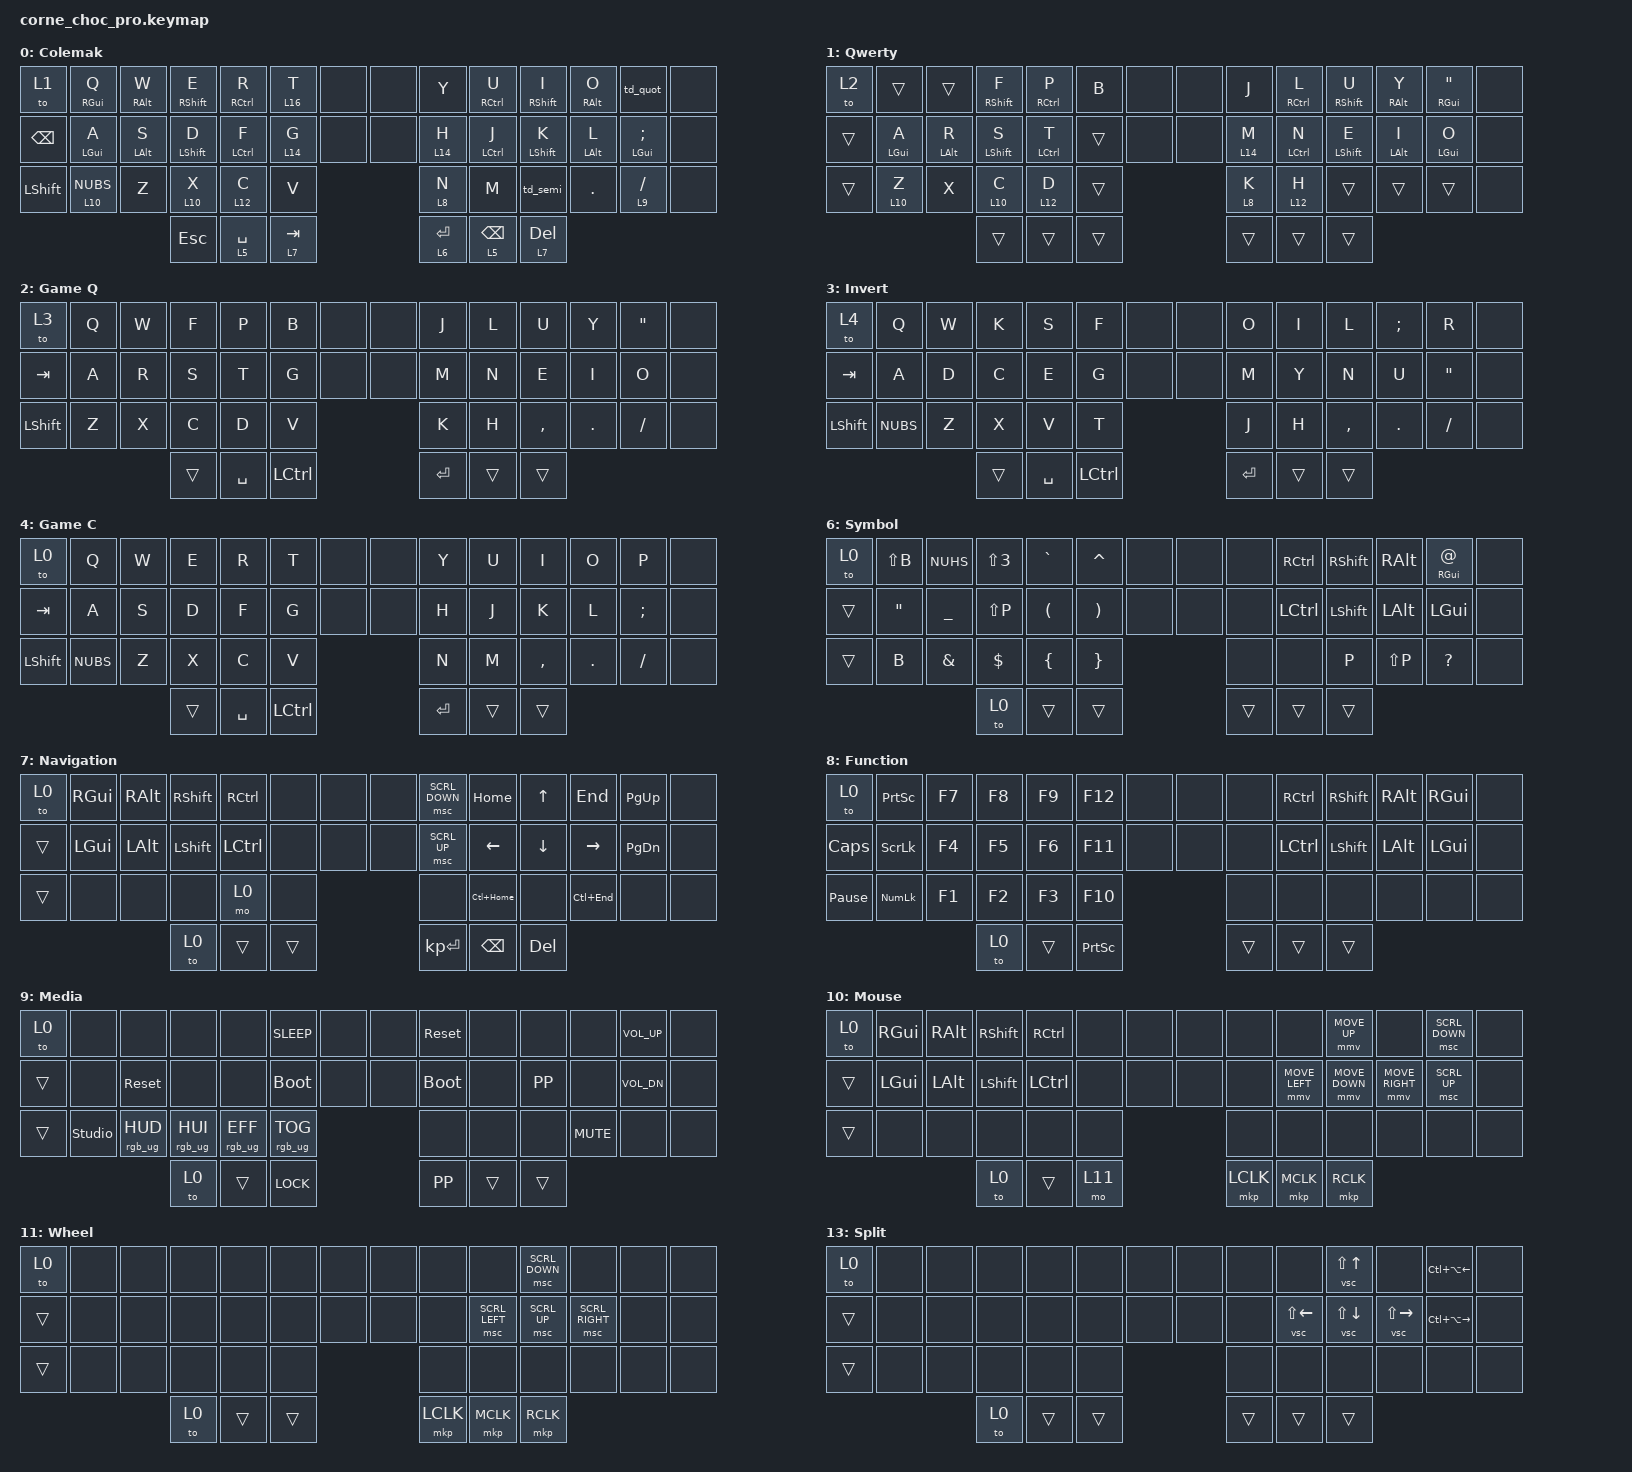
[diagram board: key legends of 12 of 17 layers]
/*
 * Copyright (c) 2020 The ZMK Contributors
 *
 * SPDX-License-Identifier: MIT
 */

#include <behaviors.dtsi>
#include <dt-bindings/zmk/bt.h>
#include <dt-bindings/zmk/keys.h>
#include <dt-bindings/zmk/pointing.h>
#include <dt-bindings/zmk/rgb.h>

// ┏━━━━━━━━━━━━━━━━━━━━━━━━━━━━━━━━━━━━━━━━━━━━━━━━━━━━━━━━━━━━━━━━━━━━━━━━━━━━━━━━━━━━━━━━━━━━━━━━━┓
// ┃                                 CORNE CHOC PRO KEYMAP CONFIGURATION                             ┃
// ┗━━━━━━━━━━━━━━━━━━━━━━━━━━━━━━━━━━━━━━━━━━━━━━━━━━━━━━━━━━━━━━━━━━━━━━━━━━━━━━━━━━━━━━━━━━━━━━━━━┛

#define BASE 0
#define QWER 1
#define QGAM 2
#define INVR 3
#define GAME 4
#define NUMB 5
#define SYMB 6
#define NAVI 7
#define FUNC 8
#define MEDI 9
#define MOUS 10
#define MWHL 11
#define CODE 12
#define CSLP 13
#define TILE 14
#define TSIZ 15
#define BLUE 16
#define TERM 17

/ {
    chosen { zmk,physical-layout = &default_layout; };

    behaviors {
        hml: home_row_mod_left {
            compatible = "zmk,behavior-hold-tap";
            #binding-cells = <2>;
            flavor = "balanced";
            require-prior-idle-ms = <200>;
            tapping-term-ms = <280>;
            quick-tap-ms = <175>;
            bindings = <&kp>, <&kp>;

            hold-trigger-key-positions = <7 8 9 10 11 12 13 21 22 23 24 25 26 34 35 36 37 38 39 40 41 42 43 44 27 45 20 6>; // List of keys on the right and thumbs
            hold-trigger-on-release;
        };

        hmr: home_row_mod_right {
            compatible = "zmk,behavior-hold-tap";
            #binding-cells = <2>;
            flavor = "balanced";
            require-prior-idle-ms = <200>;
            tapping-term-ms = <280>;
            quick-tap-ms = <175>;
            bindings = <&kp>, <&kp>;

            hold-trigger-key-positions = <0 1 2 3 4 5 6 14 15 16 17 18 19 28 29 30 31 32 40 41 42 43 44 19 20 33 21 7 45>; // List of keys on the left and thumbs
            hold-trigger-on-release;
        };

        td_quot: td_quot {
            compatible = "zmk,behavior-tap-dance";
            label = "TD_QUOT";
            #binding-cells = <0>;
            bindings = <&mt RGUI P>, <&kp AT>;
        };

        td_semi: td_semi {
            compatible = "zmk,behavior-tap-dance";
            label = "TD_SEMI";
            #binding-cells = <0>;
            bindings = <&kp COMMA>, <&kp P>;
        };
    };

    macros {
        vsc: visual_studio_code {
            compatible = "zmk,behavior-macro-one-param";
            #binding-cells = <1>;
            bindings = <&kp LC(N) &macro_param_1to1 &kp MACRO_PLACEHOLDER>;
        };
    };
};

/ {
    combos {
        compatible = "zmk,combos";

        AA {
            bindings = <&kp RA(W)>;
            key-positions = <11 12>;
        };

        AE {
            bindings = <&kp RA(R)>;
            key-positions = <11 10>;
        };

        OE {
            bindings = <&kp RA(NUBS)>;
            key-positions = <26 25>;
        };
    };

    keymap {
        compatible = "zmk,keymap";

        default_layer {
            // ┏━━━━━━━━━━━━━━━━━━━━━━━━━━━━━━━━━━━━━━━━━━━━━━━━━┓
            // ┃                                                 ┃

            label = "BASE";           //               ┃
            display-name = "Colemak"; //               ┃
            // ┃      note: If OS layout is COLEMAK              ┃
            // ┃                                                 ┃
            // ┗━━━━━━━━━━━━━━━━━━━━━━━━━━━━━━━━━━━━━━━━━━━━━━━━━┛
            // --------------------------------------------------------------------------------
            // | QWER |  Q  |  W  |  F  |  P  |  B  |     |     |  J  |  L   |  U  |  Y  |  '  |  |
            // | BSPC |  A  |  R  |  S  |  T  |  G  |     |     |  M  |  N   |  E  |  I  |  O  |  |
            // | SHFT |  Z  |  X  |  C  |  D  |  V  |           |  K  |  H   |  ,  |  .  |  /  |  |
            //                    | ESC | SPC | TAB |           | ENT | BSPC | DEL |
            // --------------------------------------------------------------------------------
            // |    | RGUI | RALT | RSHFT | RCTRL | BLUE |     |     |      | RCTRL | RSHFT | RALT | RGUI |  |
            // |    | GUI  | ALT  | SHFT  | CTRL  | TILE |     |     | TILE | CTRL  | SHFT  | ALT  | GUI  |  |
            // |    |      |      | MOUSE | CODE  | FUNC |           | FUNC | CODE  |       | COMP | MEDI |  |
            //                    |       | NUMB  | NAVI |           | SYMB | NUMB  | NAVI  |

            bindings = <
&to 1      &hml RGUI Q  &hml RALT W  &hml RSHFT E  &hml RCTRL R  &lt 16 T   &none  &none  &kp Y      &hmr RCTRL U  &hmr RSHFT I  &hmr RALT O  &td_quot        &none
&kp BSPC   &hml LGUI A  &hml LALT S  &hml LSHFT D  &hml LCTRL F  &lt 14 G   &none  &none  &lt 14 H   &hmr LCTRL J  &hmr LSHFT K  &hmr LALT L  &hmr LGUI SEMI  &none
&kp LSHFT  &lt 10 NUBS  &kp Z        &lt 10 X      &lt 12 C      &kp V                    &lt 8 N    &kp M         &td_semi      &kp DOT      &lt 9 FSLH      &none
                                     &kp ESC       &lt 5 SPACE   &lt 7 TAB                &lt 6 RET  &lt 5 BSPC    &lt 7 DEL
            >;

            sensor-bindings = <&inc_dec_kp C_VOL_DN C_VOL_UP &inc_dec_kp PG_UP PG_DN &inc_dec_kp C_PREV C_NEXT &inc_dec_kp C_BRI_DN C_BRI_UP>;
        };

        qwerty_layer {
            // ┏━━━━━━━━━━━━━━━━━━━━━━━━━━━━━━━━━━━━━━━━━━━━━━━━━┓
            // ┃                                                 ┃

            label = "QWER";          //                ┃
            display-name = "Qwerty"; //                ┃
            // ┃      note: If OS layout is QWERTY               ┃
            // ┃                                                 ┃
            // ┗━━━━━━━━━━━━━━━━━━━━━━━━━━━━━━━━━━━━━━━━━━━━━━━━━┛
            // -----------------------------------------------------------------------------------------
            // | QGAM |  Q  |  W  |  E  |  R  |  T   |       |       |  Y  |  U   |  I  |  O  |  P  |   |
            // | BSPC |  A  |  S  |  D  |  F  |  G   |       |       |  H  |  J   |  K  |  L  |  '  |   |
            // | SHFT |  Z  |  X  |  C  |  V  |  B   |               |  N  |  M   |  ,  |  .  |  /  |   |
            //                    | ESC | SPC | TAB  |               | ENT | BSPC | DEL |
            // -----------------------------------------------------------------------------------------
            // |    | RGUI | RALT | RSHFT | RCTRL | BLUE |     |     |      | RCTRL | RSHFT | RALT | RGUI |  |
            // |    | GUI  | ALT  | SHFT  | CTRL  | TILE |     |     | TILE | CTRL  | SHFT  | ALT  | GUI  |  |
            // |    |      | COMP |       | CODE  | FUNC |           | FUNC | CODE  |       | COMP | MEDI |  |
            //                    |       | NUMB  | NAVI |           | SYMB | NUMB  | NAVI  |

            bindings = <
&to 2   &trans       &trans       &hml RSHFT F  &hml RCTRL P  &kp B   &none  &none  &kp J     &hmr RCTRL L  &hmr RSHFT U  &hmr RALT Y  &hmr RGUI DQT  &none
&trans  &hml LGUI A  &hml LALT R  &hml LSHFT S  &hml LCTRL T  &trans  &none  &none  &lt 14 M  &hmr LCTRL N  &hmr LSHFT E  &hmr LALT I  &hmr LGUI O    &none
&trans  &lt 10 Z     &kp X        &lt 10 C      &lt 12 D      &trans                &lt 8 K   &lt 12 H      &trans        &trans       &trans         &none
                                  &trans        &trans        &trans                &trans    &trans        &trans
            >;

            sensor-bindings = <&inc_dec_kp C_VOL_DN C_VOL_UP &inc_dec_kp PG_UP PG_DN &inc_dec_kp C_PREV C_NEXT &inc_dec_kp C_BRI_DN C_BRI_UP>;
        };

        qwerty_game_layer {
            // ┏━━━━━━━━━━━━━━━━━━━━━━━━━━━━━━━━━━━━━━━━━━━━━━━━━┓
            // ┃                                                 ┃

            label = "QGAM";          //                ┃
            display-name = "Game Q"; //                ┃
            // ┃                                                 ┃
            // ┗━━━━━━━━━━━━━━━━━━━━━━━━━━━━━━━━━━━━━━━━━━━━━━━━━┛
            // -----------------------------------------------------------------------------------------
            // | INVR |  Q  |  W  |  E  |  R  |  T   |       |       |  Y  |  U   |  I  |  O  |  P  |   |
            // | CTRL |  A  |  S  |  D  |  F  |  G   |       |       |  H  |  J   |  K  |  L  |  '  |   |
            // | SHFT |  Z  |  X  |  C  |  V  |  B   |               |  N  |  M   |  ,  |  .  |  /  |   |
            //                    | ESC | SPC | TAB  |               | ENT | BSPC | DEL |
            // -----------------------------------------------------------------------------------------
            // |      |     |     |     |     |     |       |       |     |      |     |     |     |      |
            // |      |     |     |     |     |     |       |       |     |      |     |     |     |      |
            // |      |     |     |     |     |     |               |     |      |     |     |     |      |
            //                    |     |     |     |               |     |      |     |

            bindings = <
&to 3      &kp Q  &kp W  &kp F   &kp P      &kp B      &none  &none  &kp J    &kp L   &kp U      &kp Y    &kp DQT   &none
&kp TAB    &kp A  &kp R  &kp S   &kp T      &kp G      &none  &none  &kp M    &kp N   &kp E      &kp I    &kp O     &none
&kp LSHFT  &kp Z  &kp X  &kp C   &kp D      &kp V                    &kp K    &kp H   &kp COMMA  &kp DOT  &kp FSLH  &none
                         &trans  &kp SPACE  &kp LCTRL                &kp RET  &trans  &trans
            >;

            sensor-bindings = <&inc_dec_kp C_VOL_DN C_VOL_UP &inc_dec_kp PG_UP PG_DN &inc_dec_kp C_PREV C_NEXT &inc_dec_kp C_BRI_DN C_BRI_UP>;
        };

        invert_game_layer {
            // ┏━━━━━━━━━━━━━━━━━━━━━━━━━━━━━━━━━━━━━━━━━━━━━━━━━┓
            // ┃                                                 ┃

            label = "INVR";          //                ┃
            display-name = "Invert"; //                ┃
            // ┃                                                 ┃
            // ┗━━━━━━━━━━━━━━━━━━━━━━━━━━━━━━━━━━━━━━━━━━━━━━━━━┛
            // -----------------------------------------------------------------------------------------
            // | GAME |  Q  |  W  |  E  |  R  |  T   |       |       |  Y  |  U   |  I  |  O  |  P  |   |
            // | CTRL |  A  |  S  |  D  |  F  |  G   |       |       |  H  |  J   |  K  |  L  |  '  |   |
            // | SHFT |  Z  |  X  |  C  |  V  |  B   |               |  N  |  M   |  ,  |  .  |  /  |   |
            //                    | ESC | SPC | TAB  |               | ENT | BSPC | DEL |
            // -----------------------------------------------------------------------------------------
            // |      |     |     |     |     |     |       |       |     |      |     |     |     |      |
            // |      |     |     |     |     |     |       |       |     |      |     |     |     |      |
            // |      |     |     |     |     |     |               |     |      |     |     |     |      |
            //                    |     |     |     |               |     |      |     |

            bindings = <
&to 4      &kp Q     &kp W  &kp K   &kp S      &kp F      &none  &none  &kp O    &kp I   &kp L      &kp SEMI  &kp R     &none
&kp TAB    &kp A     &kp D  &kp C   &kp E      &kp G      &none  &none  &kp M    &kp Y   &kp N      &kp U     &kp DQT   &none
&kp LSHFT  &kp NUBS  &kp Z  &kp X   &kp V      &kp T                    &kp J    &kp H   &kp COMMA  &kp DOT   &kp FSLH  &none
                            &trans  &kp SPACE  &kp LCTRL                &kp RET  &trans  &trans
            >;

            sensor-bindings = <&inc_dec_kp C_VOL_DN C_VOL_UP &inc_dec_kp PG_UP PG_DN &inc_dec_kp C_PREV C_NEXT &inc_dec_kp C_BRI_DN C_BRI_UP>;
        };

        colemak_game_layer {
            // ┏━━━━━━━━━━━━━━━━━━━━━━━━━━━━━━━━━━━━━━━━━━━━━━━━━┓
            // ┃                                                 ┃

            label = "GAME";
            display-name = "Game C";

            // ┃                                                 ┃
            // ┗━━━━━━━━━━━━━━━━━━━━━━━━━━━━━━━━━━━━━━━━━━━━━━━━━┛
            // -----------------------------------------------------------------------------------------
            // | BASE |  Q  |  W  |  F  |  P  |  B   |     |     |  J  |  L   |  U  |  Y  |  '  |  |
            // | CTRL |  A  |  R  |  S  |  T  |  G   |     |     |  M  |  N   |  E  |  I  |  O  |  |
            // | SHFT |  Z  |  X  |  C  |  D  |  V   |           |  K  |  H   |  ,  |  .  |  /  |  |
            //                    | ESC | SPC | TAB  |           | ENT | BSPC | DEL |
            // -----------------------------------------------------------------------------------------
            // |      |     |     |     |     |     |       |       |     |      |     |     |     |   |
            // |      |     |     |     |     |     |       |       |     |      |     |     |     |   |
            // |      |     |     |     |     |     |               |     |      |     |     |     |   |
            //                    |     |     |     |               |     |      |     |

            bindings = <
&to 0      &kp Q     &kp W  &kp E   &kp R      &kp T      &none  &none  &kp Y    &kp U   &kp I      &kp O    &kp P     &none
&kp TAB    &kp A     &kp S  &kp D   &kp F      &kp G      &none  &none  &kp H    &kp J   &kp K      &kp L    &kp SEMI  &none
&kp LSHFT  &kp NUBS  &kp Z  &kp X   &kp C      &kp V                    &kp N    &kp M   &kp COMMA  &kp DOT  &kp FSLH  &none
                            &trans  &kp SPACE  &kp LCTRL                &kp RET  &trans  &trans
            >;

            sensor-bindings = <&inc_dec_kp C_VOL_DN C_VOL_UP &inc_dec_kp PG_UP PG_DN &inc_dec_kp C_PREV C_NEXT &inc_dec_kp C_BRI_DN C_BRI_UP>;
        };

        number_layer {
            // ┏━━━━━━━━━━━━━━━━━━━━━━━━━━━━━━━━━━━━━━━━━━━━━━━━━┓
            // ┃                                                 ┃

            label = "NUMB";
            display-name = "Number";

            // ┃                                                 ┃
            // ┗━━━━━━━━━━━━━━━━━━━━━━━━━━━━━━━━━━━━━━━━━━━━━━━━━┛
            // -----------------------------------------------------------------------------------------
            // | BASE |  !  |     |      |     |     |       |       |     |  7  |  8  |  9  |  0  |   |
            // |      |  +  |  =  | "-"  |  <  |  >  |       |       |  ,  |  4  |  5  |  6  |     |   |
            // |      |  ~  |  %  |  *   |  [  |  ]  |               |  .  |  1  |  2  |  3  |  /  |   |
            //                    | BASE | SPC | TAB |               | ENT |  0  | DEL |
            // -----------------------------------------------------------------------------------------
            // |      | RGUI | RALT | RSHF | RCTL |     |       |       |     | RCTL | RSHF | RALT | RGUI |   |
            // |      | GUI  | ALT  | SHFT | CTRL |     |       |       |     | CTRL | SHFT | ALT  | GUI  |   |
            // |      |      |      |      |      |     |               |     |      |      |      |      |   |
            //                      |      |      |     |               |     |      |      |

            bindings = <
&to 0   &mt RGUI EXCL  &kp RALT        &kp RSHFT        &kp RCTRL     &none     &none  &none  &kp LS(SEMICOLON)  &mt RCTRL N7  &mt RSHFT N8  &mt RALT N9  &mt (RGUI) LS(LC(UP_ARROW))    &none
&trans  &mt LGUI PLUS  &mt LALT EQUAL  &mt LSHFT MINUS  &mt LCTRL LT  &kp GT    &none  &none  &kp COMMA          &mt LCTRL N4  &mt LSHFT N5  &mt LALT N6  &mt (LGUI) LS(LC(DOWN_ARROW))  &none
&trans  &kp PIPE       &kp PRCNT       &kp STAR         &kp LBKT      &kp RBKT                &kp DOT            &kp N1        &kp N2        &kp N3       &kp FSLH                       &none
                                       &to 0            &kp SPACE     &kp TAB                 &kp RET            &kp N0        &trans
            >;
        };

        symbol_layer {
            // ┏━━━━━━━━━━━━━━━━━━━━━━━━━━━━━━━━━━━━━━━━━━━━━━━━━┓
            // ┃                                                 ┃

            label = "SYMB";
            display-name = "Symbol";

            // ┃                                                 ┃
            // ┗━━━━━━━━━━━━━━━━━━━━━━━━━━━━━━━━━━━━━━━━━━━━━━━━━┛
            // -----------------------------------------------------------------------------------------
            // | BASE | "|" |  #  |  £  |  `  |  "  |       |       |  ^  |      |      |     |  "  |   |
            // |      |  @  |  _  |  :  |  (  |  )  |       |       |     |      |      |     |     |   |
            // |      |  \  |  &  |  $  |  {  |  }  |               |     |      |  ;   |  :  |  ?  |   |
            //                    |     |     |     |               |     |      |      |
            // -----------------------------------------------------------------------------------------
            // |      |     |     |     |     |     |       |       |     |      |      |     |     |   |
            // |      |     |     |     |     |     |       |       |     | CTRL | SHFT | ALT | GUI |   |
            // |      |     |     |     |     |     |               |     |      |      |     |     |   |
            //                    |     |     |     |               |     |      |      |

            bindings = <
&to 0   &kp LS(B)  &kp NUHS   &kp LS(N3)  &kp GRAVE  &kp CARET  &none  &none  &none   &kp RCTRL  &kp RSHFT  &kp RALT   &mt RGUI AT  &none
&trans  &kp DQT    &kp UNDER  &kp LS(P)   &kp LPAR   &kp RPAR   &none  &none  &none   &kp LCTRL  &kp LSHFT  &kp LALT   &kp LGUI     &none
&trans  &kp B      &kp AMPS   &kp DLLR    &kp LBRC   &kp RBRC                 &none   &none      &kp P      &kp LS(P)  &kp QMARK    &none
                              &to 0       &trans     &trans                   &trans  &trans     &trans
            >;
        };

        navigation_layer {
            // ┏━━━━━━━━━━━━━━━━━━━━━━━━━━━━━━━━━━━━━━━━━━━━━━━━━┓
            // ┃                                                 ┃

            label = "NAV";
            display-name = "Navigation";

            // ┃                                                 ┃
            // ┗━━━━━━━━━━━━━━━━━━━━━━━━━━━━━━━━━━━━━━━━━━━━━━━━━┛
            // -----------------------------------------------------------------------------------------
            // | BASE |      |      |      |      |      |     |     | TOP | HOME |  UP  | END   | PGUP |   |
            // |      | SEL  | LOAD | SAVE | NWTB |      |     |     | <<  | LEFT | DOWN | RIGHT | PGDN |   |
            // |      | UNDO | CUT  | COPY | PAST | REDO |           |     | TOP  |      | BTTM  |      |   |
            //                      |      |      |      |           |     |      |      |
            // -----------------------------------------------------------------------------------------
            // |      | RGUI | RALT | RSHF | RCTL |     |     |     |     |      |     |     |     |   |
            // |      | GUI  | ALT  | SHFT | CTRL |     |     |     |     |      |     |     |     |   |
            // |      |      |      |      |      |     |           |     |      |     |     |     |   |
            //                      |      |      |     |           |     |      |     |

            bindings = <
&to 0   &kp RGUI  &kp RALT  &kp RSHIFT  &kp RCTRL  &none   &none  &none  &msc SCRL_DOWN  &kp HOME       &kp UP      &kp END      &kp PG_UP  &none
&trans  &kp LGUI  &kp LALT  &kp LSHFT   &kp LCTRL  &none   &none  &none  &msc SCRL_UP    &kp LEFT       &kp DOWN    &kp RIGHT    &kp PG_DN  &none
&trans  &none     &none     &none       &mo 0      &none                 &none           &kp LC(HOME)   &none       &kp LC(END)  &none      &none
                            &to 0       &trans     &trans                &kp KP_ENTER    &kp BACKSPACE  &kp DELETE
            >;
        };

        function_layer {
            // ┏━━━━━━━━━━━━━━━━━━━━━━━━━━━━━━━━━━━━━━━━━━━━━━━━━┓
            // ┃                                                 ┃

            label = "FUNC";
            display-name = "Function";

            // ┃                                                 ┃
            // ┗━━━━━━━━━━━━━━━━━━━━━━━━━━━━━━━━━━━━━━━━━━━━━━━━━┛
            // -----------------------------------------------------------------------------------------
            // | BASE | PRNT | f12 | f7 | f8  | f9 | f12 |     |     |     |     |     |     |     |   |
            // | CAPS | SCLK | f11 | f4 | f5  | f6 | f11 |     |     |     |     |     |     |     |   |
            // | PAUS | NMLK | f10 | f1 | f2  | f3 | f10 |           |     |     |     |     |     |   |
            //                          |     |    |     |           |     |     |     |
            // -----------------------------------------------------------------------------------------
            // |      |     |     |     |     |     |     |     |     | RCTL | RSHF | RALT | RGUI |   |
            // |      |     |     |     |     |     |     |     |     | CTRL | SHFT | ALT  | GUI  |   |
            // |      |     |     |     |     |     |           |     |      |      |      |      |   |
            //                    |     |     |     |           |     |      |      |

            bindings = <
&to 0            &kp PSCRN   &kp F7  &kp F8  &kp F9  &kp F12    &none  &none  &none   &kp RCTRL  &kp RSHFT  &kp RALT  &kp RGUI  &none
&kp CAPS         &kp SLCK    &kp F4  &kp F5  &kp F6  &kp F11    &none  &none  &none   &kp LCTRL  &kp LSHFT  &kp LALT  &kp LGUI  &none
&kp PAUSE_BREAK  &kp KP_NUM  &kp F1  &kp F2  &kp F3  &kp F10                  &none   &none      &none      &none     &none     &none
                                     &to 0   &trans  &kp PSCRN                &trans  &trans     &trans
            >;
        };

        media_layer {
            // ┏━━━━━━━━━━━━━━━━━━━━━━━━━━━━━━━━━━━━━━━━━━━━━━━━━┓
            // ┃                                                 ┃

            label = "MEDI";
            display-name = "Media";

            // ┃                                                 ┃
            // ┗━━━━━━━━━━━━━━━━━━━━━━━━━━━━━━━━━━━━━━━━━━━━━━━━━┛
            // -----------------------------------------------------------------------------------------
            // | BASE |        |      |      |       |  PWR   |     |     |      |      |      |      | VOL+ |   |
            // |      |        | RSET |      |       |  BOOT  |     |     | BOOT |      | PLAY |      | VOL- |   |
            // |      | STUDIO | Hue- | Hue+ | Effct | RgbTog |           |      |      |      | MUTE |      |   |
            //                        |      |       |  LOCK  |           | PLAY |      |      |
            // -----------------------------------------------------------------------------------------
            // |      |     |     |     |     |     |      |      |     |      |     |     |     |   |
            // |      |     |     |     |     |     |      |      |     |      |     |     |     |   |
            // |      |     |     |     |     |     |             |     |      |     |     |     |   |
            //                    |     |     |     |             |     |      |     |

            bindings = <
&to 0   &none           &none            &none            &none            &kp K_SLEEP      &none  &none  &sys_reset   &none   &none     &none       &kp C_VOL_UP  &none
&trans  &none           &sys_reset       &none            &none            &bootloader      &none  &none  &bootloader  &none   &kp K_PP  &none       &kp C_VOL_DN  &none
&trans  &studio_unlock  &rgb_ug RGB_HUD  &rgb_ug RGB_HUI  &rgb_ug RGB_EFF  &rgb_ug RGB_TOG                &none        &none   &none     &kp K_MUTE  &none         &none
                                         &to 0            &trans           &kp K_LOCK                     &kp K_PP     &trans  &trans
            >;
        };

        mouse_layer {
            // ┏━━━━━━━━━━━━━━━━━━━━━━━━━━━━━━━━━━━━━━━━━━━━━━━━━┓
            // ┃                                                 ┃

            label = "MOUS";
            display-name = "Mouse";

            // ┃                                                 ┃
            // ┗━━━━━━━━━━━━━━━━━━━━━━━━━━━━━━━━━━━━━━━━━━━━━━━━━┛
            // -----------------------------------------------------------------------------------------
            // | BASE |     |     |     |     |     |     |     |      |       | MsUp |      | WhDn |   |
            // |      |     |     |     |     |     |     |     |      |  MLft | MDwn | MRig | WhUp |   |
            // |      |     |     |     |     |     |           |      |       |      |      |      |   |
            //                    |     |     |     |           | LClk | MClk  | RClk |
            // -----------------------------------------------------------------------------------------
            // |      | RGUI | RALT | RSHF | RCTL |     |     |     |     |      |     |     |     |   |
            // |      | GUI  | ALT  | SHFT | CTRL |     |     |     |     |      |     |     |     |   |
            // |      |      |      |      |      |     |           |     |      |     |     |     |   |
            //                      |      |      |     |           |     |      |     |

            bindings = <
&to 0   &kp RGUI  &kp RALT  &kp RSHFT  &kp RCTRL  &none   &none  &none  &none      &none           &mmv MOVE_UP    &none            &msc SCRL_DOWN  &none
&trans  &kp LGUI  &kp LALT  &kp LSHFT  &kp LCTRL  &none   &none  &none  &none      &mmv MOVE_LEFT  &mmv MOVE_DOWN  &mmv MOVE_RIGHT  &msc SCRL_UP    &none
&trans  &none     &none     &none      &none      &none                 &none      &none           &none           &none            &none           &none
                            &to 0      &trans     &mo 11                &mkp LCLK  &mkp MCLK       &mkp RCLK
            >;
        };

        mouse_wheel_layer {
            // ┏━━━━━━━━━━━━━━━━━━━━━━━━━━━━━━━━━━━━━━━━━━━━━━━━━┓
            // ┃                                                 ┃

            label = "MWHL";
            display-name = "Wheel";

            // ┃                                                 ┃
            // ┗━━━━━━━━━━━━━━━━━━━━━━━━━━━━━━━━━━━━━━━━━━━━━━━━━┛
            // -----------------------------------------------------------------------------------------
            // | BASE |     |     |     |     |     |     |     |      |       | WhDw |      |     |   |
            // |      |     |     |     |     |     |     |     |      |  Whft | WhUp | WhRg |     |   |
            // |      |     |     |     |     |     |           |      |       |      |      |     |   |
            //                    |     |     |     |           | LClk | MClk  | RClk |
            // -----------------------------------------------------------------------------------------
            // |      |     |     |     |     |     |       |       |     |      |     |     |     |   |
            // |      |     |     |     |     |     |       |       |     |      |     |     |     |   |
            // |      |     |     |     |     |     |               |     |      |     |     |     |   |
            //                    |     |     |     |               |     |      |     |

            bindings = <
&to 0   &none  &none  &none  &none   &none   &none  &none  &none      &none           &msc SCRL_DOWN  &none            &none  &none
&trans  &none  &none  &none  &none   &none   &none  &none  &none      &msc SCRL_LEFT  &msc SCRL_UP    &msc SCRL_RIGHT  &none  &none
&trans  &none  &none  &none  &none   &none                 &none      &none           &none           &none            &none  &none
                      &to 0  &trans  &trans                &mkp LCLK  &mkp MCLK       &mkp RCLK
            >;
        };

        code_layer {
            // ┏━━━━━━━━━━━━━━━━━━━━━━━━━━━━━━━━━━━━━━━━━━━━━━━━━┓
            // ┃                                                 ┃

            label = "CODE";
            display-name = "Code";

            // ┃                                                 ┃
            // ┗━━━━━━━━━━━━━━━━━━━━━━━━━━━━━━━━━━━━━━━━━━━━━━━━━┛
            // -----------------------------------------------------------------------------------------
            // | BASE |     |     |      |     |      |     |     | Impl | Ref | Dupe Up |     |     |   |
            // |      |     |     | Save |     | TMED |     |     |      |     | Dupe Dn |     |     |   |
            // |      |     |     |      |     | TERM |           |      |     |         |     |     |   |
            //                    |      |     |      |           |      |     |         |
            // -----------------------------------------------------------------------------------------
            // |      |     |     |     |     |     |     |     |     |      |     |     |     |   |
            // |      |     |     |     |     |     |     |     |     |      |     |     |     |   |
            // |      |     |     |     |     |     |           |     |      |     |     |     |   |
            //                    |     |     |     |           |     |      |     |

            bindings = <
&to 0   &none  &none  &none   &none   &none              &none  &none  &kp LC(F12)    &kp LS(LA(F12))  &vsc LC(LS(UP))    &none  &kp LS(LC(UP))    &none
&trans  &none  &none  &vsc R  &none   &kp LC(LS(LA(K)))  &none  &none  &none          &none            &vsc LC(LS(DOWN))  &none  &kp LS(LC(DOWN))  &none
&trans  &none  &none  &none   &none   &kp LC(GRAVE)                    &kp LC(LS(N))  &none            &none              &none  &kp LC(FSLH)      &none
                      &to 0   &trans  &none                            &mo 13         &trans           &trans
            >;
        };

        codesplit_layer {
            // ┏━━━━━━━━━━━━━━━━━━━━━━━━━━━━━━━━━━━━━━━━━━━━━━━━━┓
            // ┃                                                 ┃

            label = "CSLP";
            display-name = "Split";

            // ┃                                                 ┃
            // ┗━━━━━━━━━━━━━━━━━━━━━━━━━━━━━━━━━━━━━━━━━━━━━━━━━┛
            // -----------------------------------------------------------------------------------------
            // | BASE |     |     |     |     |     |     |     |     |      | SpUp |      |     |   |
            // |      |     |     |     |     |     |     |     |     | SpLt | SpDn | SpRg |     |   |
            // |      |     |     |     |     |     |           |     |      |     |       |     |   |
            //                    |     |     |     |           |     |      |     |
            // -----------------------------------------------------------------------------------------
            // |      |     |     |     |     |     |     |     |     |      |     |     |     |   |
            // |      |     |     |     |     |     |     |     |     |      |     |     |     |   |
            // |      |     |     |     |     |     |           |     |      |     |     |     |   |
            //                    |     |     |     |           |     |      |     |

            bindings = <
&to 0   &none  &none  &none  &none   &none   &none  &none  &none   &none          &vsc LS(UP)    &none           &kp LC(LA(LEFT))   &none
&trans  &none  &none  &none  &none   &none   &none  &none  &none   &vsc LS(LEFT)  &vsc LS(DOWN)  &vsc LS(RIGHT)  &kp LC(LA(RIGHT))  &none
&trans  &none  &none  &none  &none   &none                 &none   &none          &none          &none           &none              &none
                      &to 0  &trans  &trans                &trans  &trans         &trans
            >;
        };

        tile_layer {
            // ┏━━━━━━━━━━━━━━━━━━━━━━━━━━━━━━━━━━━━━━━━━━━━━━━━━┓
            // ┃                                                 ┃

            label = "TILE";
            display-name = "Tiling";

            // ┃                                                 ┃
            // ┗━━━━━━━━━━━━━━━━━━━━━━━━━━━━━━━━━━━━━━━━━━━━━━━━━┛
            // -----------------------------------------------------------------------------------------
            // | BASE |     | SCRCT |     | WRKS- | WRKS+ |    |    |      | THOM  |  TUP  | TEND   | TPGUP |   |
            // |      |     |       |     |       |       |    |    |      | TLEFT | TDOWN | TRIGHT | TPGDW |   |
            // |      |     |       |     |       |       |         |      |       |       |        |       |   |
            //                      |     |       |       |         | SIZE |       |       |
            // -----------------------------------------------------------------------------------------
            // |      |     |     |      |      |     |       |       |     |      |     |     |     |   |
            // |      |     | ALT | SHFT | CTRL |     |       |       |     |      |     |     |     |   |
            // |      |     |     |      |      |     |               |     |      |     |     |     |   |
            //                    |      |      |     |               |     |      |     |

            bindings = <
&to 0   &none  &kp LG(W)  &kp LS(LC(LEFT_BRACKET))           &kp LG(GRAVE)  &kp LG(LS(GRAVE))  &none  &none  &none   &kp LG(HOME)  &kp LG(UP)    &kp LG(END)    &kp LG(PG_UP)  &none
&trans  &none  &kp LALT   &mt (LSHFT) LS(LC(RIGHT_BRACKET))  &kp LCTRL      &none              &none  &none  &none   &kp LG(LEFT)  &kp LG(DOWN)  &kp LG(RIGHT)  &kp LG(PG_DN)  &none
&trans  &none  &none      &none                              &none          &none                            &none   &none         &none         &none          &none          &none
                          &to 0                              &trans         &trans                           &mo 15  &trans        &trans
            >;
        };

        tilesize_layer {
            // ┏━━━━━━━━━━━━━━━━━━━━━━━━━━━━━━━━━━━━━━━━━━━━━━━━━┓
            // ┃                                                 ┃

            label = "TSIZ";
            display-name = "Tile Size";

            // ┃                                                 ┃
            // ┗━━━━━━━━━━━━━━━━━━━━━━━━━━━━━━━━━━━━━━━━━━━━━━━━━┛
            // -----------------------------------------------------------------------------------------
            // | BASE |     |     |     |     |     |     |     |     |       | VERT+ |       |     |   |
            // |      |     |     |     |     |     |     |     |     | HORZ- | VERT- | HORZ+ |     |   |
            // |      |     |     |     |     |     |           |     |       |       |       |     |   |
            //                    |     |     |     |           |     |       |       |
            // -----------------------------------------------------------------------------------------
            // |      |     |     |     |     |     |     |     |     |      |     |     |     |   |
            // |      |     |     |     |     |     |     |     |     |      |     |     |     |   |
            // |      |     |     |     |     |     |           |     |      |     |     |     |   |
            //                    |     |     |     |           |     |      |     |

            bindings = <
&to 0   &none  &kp LS(LC(F7))  &kp LC(LS(B))  &kp LS(LC(F8))  &none   &none  &none  &none   &none          &kp LG(LS(EQUAL))  &none          &none  &none
&trans  &none  &kp LS(LC(F4))  &kp LS(LC(F))  &kp LS(LC(F5))  &none   &none  &none  &none   &kp LG(MINUS)  &kp LG(LS(MINUS))  &kp LG(EQUAL)  &none  &none
&trans  &none  &kp LS(LC(F1))  &none          &kp LC(LS(F2))  &none                 &none   &none          &none              &none          &none  &none
                               &to 0          &trans          &trans                &trans  &trans         &trans
            >;
        };

        bluetooth_layer {
            // ┏━━━━━━━━━━━━━━━━━━━━━━━━━━━━━━━━━━━━━━━━━━━━━━━━━┓
            // ┃                                                 ┃

            label = "BLUE";
            display-name = "Bluetooth";

            // ┃                                                 ┃
            // ┗━━━━━━━━━━━━━━━━━━━━━━━━━━━━━━━━━━━━━━━━━━━━━━━━━┛
            // -----------------------------------------------------------------------------------------
            // | BASE |    |     |    |    |     |     |     | BTCL |     |     |     |     |   |
            // |      |    |     |    |    |     |     |     |      |     |     |     |     |   |
            // |      |    |     |    |    |     |           |      | BT0 | BT1 | BT2 |     |   |
            //                   |    |    |     |           |      |     |     |

            bindings = <
&to 0  &none  &none  &none  &none  &none  &none  &none  &bt BT_CLR  &none         &none         &none         &none         &none
&none  &none  &none  &none  &none  &none  &none  &none  &none       &none         &none         &none         &none         &none
&none  &none  &none  &none  &none  &none                &none       &bt BT_SEL 0  &bt BT_SEL 1  &bt BT_SEL 2  &bt BT_SEL 3  &none
                     &to 0  &none  &none                &none       &none         &none
            >;
        };
    };
};
